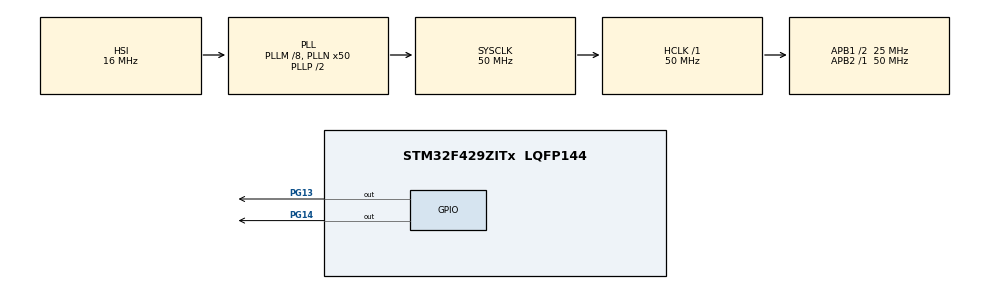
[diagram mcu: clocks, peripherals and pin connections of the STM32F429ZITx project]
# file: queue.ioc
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FREERTOS.Queues01=myQueue01,16,uint16_t,0,Dynamic,NULL,NULL
FREERTOS.Tasks01=send_message,24,128,Start_send_message,Default,NULL,Dynamic,NULL,NULL;recive_message,8,128,Start_recive_message,Default,NULL,Dynamic,NULL,NULL
FREERTOS.configUSE_NEWLIB_REENTRANT=1
Mcu.Family=STM32F4
Mcu.Name=STM32F429ZITx
Mcu.Package=LQFP144
NVIC.PriorityGroup=NVIC_PRIORITYGROUP_4
NVIC.TIM1_UP_TIM10_IRQn=true\:15\:0\:false\:false\:true\:false\:false\:true\:true
NVIC.TimeBase=TIM1_UP_TIM10_IRQn
NVIC.TimeBaseIP=TIM1
PG13.Signal=GPIO_Output
PG14.Signal=GPIO_Output
PH0/OSC_IN.Mode=HSE-External-Oscillator
PH0/OSC_IN.Signal=RCC_OSC_IN
PH1/OSC_OUT.Mode=HSE-External-Oscillator
PH1/OSC_OUT.Signal=RCC_OSC_OUT
ProjectManager.HeapSize=0x200
ProjectManager.StackSize=0x400
ProjectManager.TargetToolchain=STM32CubeIDE
RCC.48MHZClocksFreq_Value=25000000
RCC.AHBFreq_Value=50000000
RCC.APB1CLKDivider=RCC_HCLK_DIV2
RCC.APB1Freq_Value=25000000
RCC.APB1TimFreq_Value=50000000
RCC.APB2Freq_Value=50000000
RCC.APB2TimFreq_Value=50000000
RCC.CortexFreq_Value=50000000
RCC.HCLKFreq_Value=50000000
RCC.HSE_VALUE=25000000
RCC.HSI_VALUE=16000000
RCC.LSE_VALUE=32768
RCC.PLLM=8
RCC.PLLN=50
RCC.SYSCLKFreq_VALUE=50000000
RCC.SYSCLKSource=RCC_SYSCLKSOURCE_PLLCLK
RCC.VCOOutputFreq_Value=100000000
VP_FREERTOS_VS_CMSIS_V2.Mode=CMSIS_V2
VP_SYS_VS_tim1.Mode=TIM1
board=custom

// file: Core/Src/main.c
/* USER CODE BEGIN Header */
/**
  ******************************************************************************
  * @file           : main.c
  * @brief          : Main program body
  ******************************************************************************
  * @attention
  *
  * Copyright (c) 2025 STMicroelectronics.
  * All rights reserved.
  *
  * This software is licensed under terms that can be found in the LICENSE file
  * in the root directory of this software component.
  * If no LICENSE file comes with this software, it is provided AS-IS.
  *
  ******************************************************************************
  */
/* USER CODE END Header */
#include "main.h"
#include "cmsis_os.h"

/* Definitions for send_message */
osThreadId_t send_messageHandle;
const osThreadAttr_t send_message_attributes = {
  .name = "send_message",
  .stack_size = 128 * 4,
  .priority = (osPriority_t) osPriorityNormal,
};
/* Definitions for recive_message */
osThreadId_t recive_messageHandle;
const osThreadAttr_t recive_message_attributes = {
  .name = "recive_message",
  .stack_size = 128 * 4,
  .priority = (osPriority_t) osPriorityNormal,
};
/* Definitions for myQueue01 */
osMessageQueueId_t myQueue01Handle;
const osMessageQueueAttr_t myQueue01_attributes = {
  .name = "myQueue01"
};

void SystemClock_Config(void);
static void MX_GPIO_Init(void);
void Start_send_message(void *argument);
void Start_recive_message(void *argument);

/* USER CODE BEGIN 0 */
typedef enum {
    LED_ON,
    LED_OFF
} LedCommand;
LedCommand cmd;
/* USER CODE END 0 */

int main(void)
{

  /* MCU Configuration--------------------------------------------------------*/

  /* Reset of all peripherals, Initializes the Flash interface and the Systick. */
  HAL_Init();

  /* Configure the system clock */
  SystemClock_Config();

  /* Initialize all configured peripherals */
  MX_GPIO_Init();

  /* Init scheduler */
  osKernelInitialize();

  /* Create the queue(s) */
  /* creation of myQueue01 */
  myQueue01Handle = osMessageQueueNew (16, sizeof(uint16_t), &myQueue01_attributes);

  /* Create the thread(s) */
  /* creation of send_message */
  send_messageHandle = osThreadNew(Start_send_message, NULL, &send_message_attributes);

  /* creation of recive_message */
  recive_messageHandle = osThreadNew(Start_recive_message, NULL, &recive_message_attributes);

  /* Start scheduler */
  osKernelStart();

  /* We should never get here as control is now taken by the scheduler */

  /* Infinite loop */
  while (1)
  {

  }
}

void SystemClock_Config(void)
{
  RCC_OscInitTypeDef RCC_OscInitStruct = {0};
  RCC_ClkInitTypeDef RCC_ClkInitStruct = {0};

  /** Configure the main internal regulator output voltage
  */
  __HAL_RCC_PWR_CLK_ENABLE();
  __HAL_PWR_VOLTAGESCALING_CONFIG(PWR_REGULATOR_VOLTAGE_SCALE3);

  /** Initializes the RCC Oscillators according to the specified parameters
  * in the RCC_OscInitTypeDef structure.
  */
  RCC_OscInitStruct.OscillatorType = RCC_OSCILLATORTYPE_HSI;
  RCC_OscInitStruct.HSIState = RCC_HSI_ON;
  RCC_OscInitStruct.HSICalibrationValue = RCC_HSICALIBRATION_DEFAULT;
  RCC_OscInitStruct.PLL.PLLState = RCC_PLL_ON;
  RCC_OscInitStruct.PLL.PLLSource = RCC_PLLSOURCE_HSI;
  RCC_OscInitStruct.PLL.PLLM = 8;
  RCC_OscInitStruct.PLL.PLLN = 50;
  RCC_OscInitStruct.PLL.PLLP = RCC_PLLP_DIV2;
  RCC_OscInitStruct.PLL.PLLQ = 4;
  if (HAL_RCC_OscConfig(&RCC_OscInitStruct) != HAL_OK)
  {
    Error_Handler();
  }

  /** Initializes the CPU, AHB and APB buses clocks
  */
  RCC_ClkInitStruct.ClockType = RCC_CLOCKTYPE_HCLK|RCC_CLOCKTYPE_SYSCLK
                              |RCC_CLOCKTYPE_PCLK1|RCC_CLOCKTYPE_PCLK2;
  RCC_ClkInitStruct.SYSCLKSource = RCC_SYSCLKSOURCE_PLLCLK;
  RCC_ClkInitStruct.AHBCLKDivider = RCC_SYSCLK_DIV1;
  RCC_ClkInitStruct.APB1CLKDivider = RCC_HCLK_DIV2;
  RCC_ClkInitStruct.APB2CLKDivider = RCC_HCLK_DIV1;

  if (HAL_RCC_ClockConfig(&RCC_ClkInitStruct, FLASH_LATENCY_1) != HAL_OK)
  {
    Error_Handler();
  }
}

static void MX_GPIO_Init(void)
{
  GPIO_InitTypeDef GPIO_InitStruct = {0};

  /* GPIO Ports Clock Enable */
  __HAL_RCC_GPIOH_CLK_ENABLE();
  __HAL_RCC_GPIOG_CLK_ENABLE();

  /*Configure GPIO pin Output Level */
  HAL_GPIO_WritePin(GPIOG, GPIO_PIN_13|GPIO_PIN_14, GPIO_PIN_RESET);

  /*Configure GPIO pins : PG13 PG14 */
  GPIO_InitStruct.Pin = GPIO_PIN_13|GPIO_PIN_14;
  GPIO_InitStruct.Mode = GPIO_MODE_OUTPUT_PP;
  GPIO_InitStruct.Pull = GPIO_NOPULL;
  GPIO_InitStruct.Speed = GPIO_SPEED_FREQ_LOW;
  HAL_GPIO_Init(GPIOG, &GPIO_InitStruct);

}

void Start_send_message(void *argument)
{
  /* USER CODE BEGIN 5 */
  /* Infinite loop */
  for(;;)
  {
	  cmd = LED_ON;
	              // Send LED_ON command
	  osMessageQueuePut(myQueue01Handle, &cmd,osPriorityNormal,osWaitForever);
	              osDelay(2000); // Wait 1 second

	              // Send LED_OFF command
	              cmd = LED_OFF;
	  osMessageQueuePut(myQueue01Handle,&cmd,osPriorityNormal ,osWaitForever);
	              osDelay(2000); // Wait 1 second

  }
  /* USER CODE END 5 */
}

void Start_recive_message(void *argument)
{
  /* USER CODE BEGIN Start_recive_message */
  /* Infinite loop */
  for(;;)
  {
	  // Receive a command from the queue
	              if (osMessageQueueGet(myQueue01Handle, &cmd,NULL,osWaitForever) == osOK) {
	                  if (cmd == LED_ON) {
	                	  HAL_GPIO_WritePin(GPIOG, GPIO_PIN_13|GPIO_PIN_14, GPIO_PIN_SET);// Turn LED on
	                  } else if (cmd == LED_OFF) {
	                	  HAL_GPIO_WritePin(GPIOG, GPIO_PIN_13|GPIO_PIN_14, GPIO_PIN_RESET); // Turn LED off
  }
  /* USER CODE END Start_recive_message */
}
  }
}

void HAL_TIM_PeriodElapsedCallback(TIM_HandleTypeDef *htim)
{
  if (htim->Instance == TIM1) {
    HAL_IncTick();
  }
}

void Error_Handler(void)
{
  __disable_irq();
  while (1)
  {
  }
}
